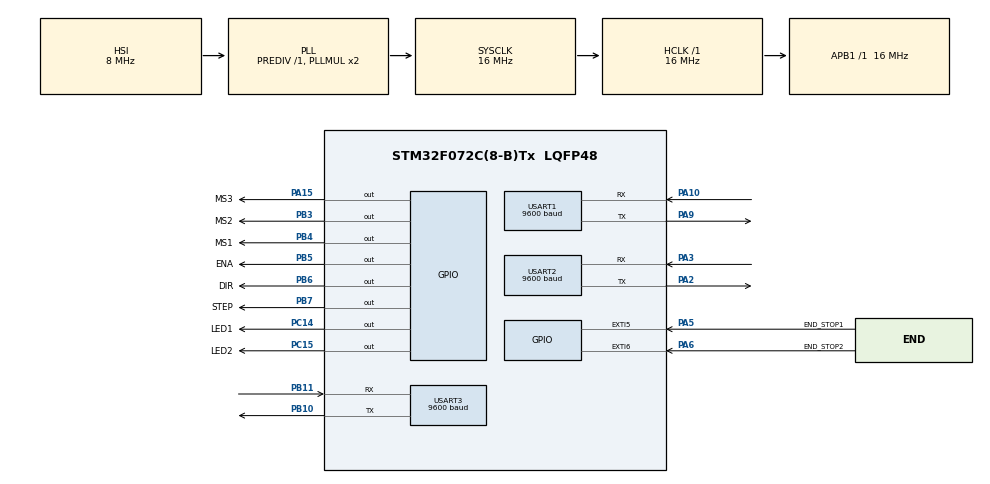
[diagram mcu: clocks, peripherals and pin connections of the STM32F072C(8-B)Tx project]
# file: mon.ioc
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Mcu.Family=STM32F0
Mcu.Name=STM32F072C(8-B)Tx
Mcu.Package=LQFP48
NVIC.EXTI4_15_IRQn=true\:0\:0\:false\:false\:true\:true
NVIC.USART1_IRQn=true\:0\:0\:false\:false\:true\:true
NVIC.USART2_IRQn=true\:0\:0\:false\:false\:true\:true
NVIC.USART3_4_IRQn=true\:0\:0\:false\:false\:true\:true
PA10.Mode=Asynchronous
PA10.Signal=USART1_RX
PA13.Mode=Serial_Wire
PA13.Signal=SYS_SWDIO
PA14.Mode=Serial_Wire
PA14.Signal=SYS_SWCLK
PA15.GPIO_Label=MS3
PA15.Signal=GPIO_Output
PA2.Mode=Asynchronous
PA2.Signal=USART2_TX
PA3.Mode=Asynchronous
PA3.Signal=USART2_RX
PA5.GPIO_Label=END_STOP1
PA5.Signal=GPXTI5
PA6.GPIO_Label=END_STOP2
PA6.Signal=GPXTI6
PA9.Mode=Asynchronous
PA9.Signal=USART1_TX
PB10.Mode=Asynchronous
PB10.Signal=USART3_TX
PB11.Mode=Asynchronous
PB11.Signal=USART3_RX
PB3.GPIO_Label=MS2
PB3.Signal=GPIO_Output
PB4.GPIO_Label=MS1
PB4.Signal=GPIO_Output
PB5.GPIO_Label=ENA
PB5.Signal=GPIO_Output
PB6.GPIO_Label=DIR
PB6.Signal=GPIO_Output
PB7.GPIO_Label=STEP
PB7.Signal=GPIO_Output
PC14-OSC32_IN.GPIO_Label=LED1
PC14-OSC32_IN.Signal=GPIO_Output
PC15-OSC32_OUT.GPIO_Label=LED2
PC15-OSC32_OUT.Signal=GPIO_Output
ProjectManager.HeapSize=0x200
ProjectManager.StackSize=0x400
ProjectManager.TargetToolchain=Makefile
RCC.AHBFreq_Value=16000000
RCC.APB1Freq_Value=16000000
RCC.APB1TimFreq_Value=16000000
RCC.HCLKFreq_Value=16000000
RCC.SYSCLKFreq_VALUE=16000000
RCC.SYSCLKSource=RCC_SYSCLKSOURCE_PLLCLK
USART1.BaudRate=9600
USART1.VirtualMode-Asynchronous=VM_ASYNC
USART1.WordLength=WORDLENGTH_8B
USART2.BaudRate=9600
USART2.VirtualMode-Asynchronous=VM_ASYNC
USART2.WordLength=WORDLENGTH_8B
USART3.BaudRate=9600
USART3.VirtualMode-Asynchronous=VM_ASYNC
USART3.WordLength=WORDLENGTH_8B
board=mon

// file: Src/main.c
/**
 ******************************************************************************
 * @file           : main.c
 * @brief          : Main program body
 ******************************************************************************
 ** This notice applies to any and all portions of this file
 * that are not between comment pairs USER CODE BEGIN and
 * USER CODE END. Other portions of this file, whether
 * inserted by the user or by software development tools
 * are owned by their respective copyright owners.
 *
 * COPYRIGHT(c) 2018 STMicroelectronics
 *
 * Redistribution and use in source and binary forms, with or without modification,
 * are permitted provided that the following conditions are met:
 *   1. Redistributions of source code must retain the above copyright notice,
 *      this list of conditions and the following disclaimer.
 *   2. Redistributions in binary form must reproduce the above copyright notice,
 *      this list of conditions and the following disclaimer in the documentation
 *      and/or other materials provided with the distribution.
 *   3. Neither the name of STMicroelectronics nor the names of its contributors
 *      may be used to endorse or promote products derived from this software
 *      without specific prior written permission.
 *
 * THIS SOFTWARE IS PROVIDED BY THE COPYRIGHT HOLDERS AND CONTRIBUTORS "AS IS"
 * AND ANY EXPRESS OR IMPLIED WARRANTIES, INCLUDING, BUT NOT LIMITED TO, THE
 * IMPLIED WARRANTIES OF MERCHANTABILITY AND FITNESS FOR A PARTICULAR PURPOSE ARE
 * DISCLAIMED. IN NO EVENT SHALL THE COPYRIGHT HOLDER OR CONTRIBUTORS BE LIABLE
 * FOR ANY DIRECT, INDIRECT, INCIDENTAL, SPECIAL, EXEMPLARY, OR CONSEQUENTIAL
 * DAMAGES (INCLUDING, BUT NOT LIMITED TO, PROCUREMENT OF SUBSTITUTE GOODS OR
 * SERVICES; LOSS OF USE, DATA, OR PROFITS; OR BUSINESS INTERRUPTION) HOWEVER
 * CAUSED AND ON ANY THEORY OF LIABILITY, WHETHER IN CONTRACT, STRICT LIABILITY,
 * OR TORT (INCLUDING NEGLIGENCE OR OTHERWISE) ARISING IN ANY WAY OUT OF THE USE
 * OF THIS SOFTWARE, EVEN IF ADVISED OF THE POSSIBILITY OF SUCH DAMAGE.
 *
 ******************************************************************************
 */
#include "main.h"
#include "stm32f0xx_hal.h"

UART_HandleTypeDef huart1;
UART_HandleTypeDef huart2;
UART_HandleTypeDef huart3;

/* USER CODE BEGIN PV */
/* Private variables ---------------------------------------------------------*/

/* USER CODE END PV */

void SystemClock_Config(void);
static void MX_GPIO_Init(void);
static void MX_USART1_UART_Init(void);
static void MX_USART2_UART_Init(void);
static void MX_USART3_UART_Init(void);

/* USER CODE BEGIN PFP */
/* Private function prototypes -----------------------------------------------*/

/* USER CODE END PFP */

int main(void)
{

    /* MCU Configuration----------------------------------------------------------*/

    /* Reset of all peripherals, Initializes the Flash interface and the Systick. */
    HAL_Init();

    /* Configure the system clock */
    SystemClock_Config();

    /* Initialize all configured peripherals */
    MX_GPIO_Init();
    MX_USART1_UART_Init();
    MX_USART2_UART_Init();
    MX_USART3_UART_Init();

    /* Infinite loop */
    while (1)
    {

    }
} /* main */

void SystemClock_Config(void)
{
    RCC_OscInitTypeDef RCC_OscInitStruct;
    RCC_ClkInitTypeDef RCC_ClkInitStruct;
    RCC_PeriphCLKInitTypeDef PeriphClkInit;

    /**Initializes the CPU, AHB and APB busses clocks
     */
    RCC_OscInitStruct.OscillatorType      = RCC_OSCILLATORTYPE_HSI;
    RCC_OscInitStruct.HSIState            = RCC_HSI_ON;
    RCC_OscInitStruct.HSICalibrationValue = 16;
    RCC_OscInitStruct.PLL.PLLState        = RCC_PLL_ON;
    RCC_OscInitStruct.PLL.PLLSource       = RCC_PLLSOURCE_HSI;
    RCC_OscInitStruct.PLL.PLLMUL          = RCC_PLL_MUL2;
    RCC_OscInitStruct.PLL.PREDIV          = RCC_PREDIV_DIV1;
    if (HAL_RCC_OscConfig(&RCC_OscInitStruct) != HAL_OK)
    {
        _Error_Handler(__FILE__, __LINE__);
    }

    /**Initializes the CPU, AHB and APB busses clocks
     */
    RCC_ClkInitStruct.ClockType = RCC_CLOCKTYPE_HCLK | RCC_CLOCKTYPE_SYSCLK
      | RCC_CLOCKTYPE_PCLK1;
    RCC_ClkInitStruct.SYSCLKSource   = RCC_SYSCLKSOURCE_PLLCLK;
    RCC_ClkInitStruct.AHBCLKDivider  = RCC_SYSCLK_DIV1;
    RCC_ClkInitStruct.APB1CLKDivider = RCC_HCLK_DIV1;

    if (HAL_RCC_ClockConfig(&RCC_ClkInitStruct, FLASH_LATENCY_0) != HAL_OK)
    {
        _Error_Handler(__FILE__, __LINE__);
    }

    PeriphClkInit.PeriphClockSelection = RCC_PERIPHCLK_USART1 | RCC_PERIPHCLK_USART2;
    PeriphClkInit.Usart1ClockSelection = RCC_USART1CLKSOURCE_PCLK1;
    PeriphClkInit.Usart2ClockSelection = RCC_USART2CLKSOURCE_PCLK1;
    if (HAL_RCCEx_PeriphCLKConfig(&PeriphClkInit) != HAL_OK)
    {
        _Error_Handler(__FILE__, __LINE__);
    }

    /**Configure the Systick interrupt time
     */
    HAL_SYSTICK_Config(HAL_RCC_GetHCLKFreq() / 1000);

    /**Configure the Systick
     */
    HAL_SYSTICK_CLKSourceConfig(SYSTICK_CLKSOURCE_HCLK);

    /* SysTick_IRQn interrupt configuration */
    HAL_NVIC_SetPriority(SysTick_IRQn, 0, 0);
} /* SystemClock_Config */

/* USART1 init function */
static void MX_USART1_UART_Init(void)
{
    huart1.Instance                    = USART1;
    huart1.Init.BaudRate               = 9600;
    huart1.Init.WordLength             = UART_WORDLENGTH_8B;
    huart1.Init.StopBits               = UART_STOPBITS_1;
    huart1.Init.Parity                 = UART_PARITY_NONE;
    huart1.Init.Mode                   = UART_MODE_TX_RX;
    huart1.Init.HwFlowCtl              = UART_HWCONTROL_NONE;
    huart1.Init.OverSampling           = UART_OVERSAMPLING_16;
    huart1.Init.OneBitSampling         = UART_ONE_BIT_SAMPLE_DISABLE;
    huart1.AdvancedInit.AdvFeatureInit = UART_ADVFEATURE_NO_INIT;
    if (HAL_UART_Init(&huart1) != HAL_OK)
    {
        _Error_Handler(__FILE__, __LINE__);
    }
}

/* USART2 init function */
static void MX_USART2_UART_Init(void)
{
    huart2.Instance                    = USART2;
    huart2.Init.BaudRate               = 9600;
    huart2.Init.WordLength             = UART_WORDLENGTH_8B;
    huart2.Init.StopBits               = UART_STOPBITS_1;
    huart2.Init.Parity                 = UART_PARITY_NONE;
    huart2.Init.Mode                   = UART_MODE_TX_RX;
    huart2.Init.HwFlowCtl              = UART_HWCONTROL_NONE;
    huart2.Init.OverSampling           = UART_OVERSAMPLING_16;
    huart2.Init.OneBitSampling         = UART_ONE_BIT_SAMPLE_DISABLE;
    huart2.AdvancedInit.AdvFeatureInit = UART_ADVFEATURE_NO_INIT;
    if (HAL_UART_Init(&huart2) != HAL_OK)
    {
        _Error_Handler(__FILE__, __LINE__);
    }
}

/* USART3 init function */
static void MX_USART3_UART_Init(void)
{
    huart3.Instance                    = USART3;
    huart3.Init.BaudRate               = 9600;
    huart3.Init.WordLength             = UART_WORDLENGTH_8B;
    huart3.Init.StopBits               = UART_STOPBITS_1;
    huart3.Init.Parity                 = UART_PARITY_NONE;
    huart3.Init.Mode                   = UART_MODE_TX_RX;
    huart3.Init.HwFlowCtl              = UART_HWCONTROL_NONE;
    huart3.Init.OverSampling           = UART_OVERSAMPLING_16;
    huart3.Init.OneBitSampling         = UART_ONE_BIT_SAMPLE_DISABLE;
    huart3.AdvancedInit.AdvFeatureInit = UART_ADVFEATURE_NO_INIT;
    if (HAL_UART_Init(&huart3) != HAL_OK)
    {
        _Error_Handler(__FILE__, __LINE__);
    }
}

/** Configure pins as
 * Analog
 * Input
 * Output
 * EVENT_OUT
 * EXTI
 */
static void MX_GPIO_Init(void)
{
    GPIO_InitTypeDef GPIO_InitStruct;

    /* GPIO Ports Clock Enable */
    __HAL_RCC_GPIOC_CLK_ENABLE();
    __HAL_RCC_GPIOA_CLK_ENABLE();
    __HAL_RCC_GPIOB_CLK_ENABLE();

    /*Configure GPIO pin Output Level */
    HAL_GPIO_WritePin(GPIOC, LED1_Pin | LED2_Pin, GPIO_PIN_RESET);

    /*Configure GPIO pin Output Level */
    HAL_GPIO_WritePin(MS3_GPIO_Port, MS3_Pin, GPIO_PIN_RESET);

    /*Configure GPIO pin Output Level */
    HAL_GPIO_WritePin(GPIOB, MS2_Pin | MS1_Pin | ENA_Pin | DIR_Pin
      | STEP_Pin, GPIO_PIN_RESET);

    /*Configure GPIO pins : LED1_Pin LED2_Pin */
    GPIO_InitStruct.Pin   = LED1_Pin | LED2_Pin;
    GPIO_InitStruct.Mode  = GPIO_MODE_OUTPUT_PP;
    GPIO_InitStruct.Pull  = GPIO_NOPULL;
    GPIO_InitStruct.Speed = GPIO_SPEED_FREQ_LOW;
    HAL_GPIO_Init(GPIOC, &GPIO_InitStruct);

    /*Configure GPIO pins : END_STOP1_Pin END_STOP2_Pin */
    GPIO_InitStruct.Pin  = END_STOP1_Pin | END_STOP2_Pin;
    GPIO_InitStruct.Mode = GPIO_MODE_IT_RISING;
    GPIO_InitStruct.Pull = GPIO_NOPULL;
    HAL_GPIO_Init(GPIOA, &GPIO_InitStruct);

    /*Configure GPIO pin : MS3_Pin */
    GPIO_InitStruct.Pin   = MS3_Pin;
    GPIO_InitStruct.Mode  = GPIO_MODE_OUTPUT_PP;
    GPIO_InitStruct.Pull  = GPIO_NOPULL;
    GPIO_InitStruct.Speed = GPIO_SPEED_FREQ_LOW;
    HAL_GPIO_Init(MS3_GPIO_Port, &GPIO_InitStruct);

    /*Configure GPIO pins : MS2_Pin MS1_Pin ENA_Pin DIR_Pin
     *                       STEP_Pin */
    GPIO_InitStruct.Pin = MS2_Pin | MS1_Pin | ENA_Pin | DIR_Pin
      | STEP_Pin;
    GPIO_InitStruct.Mode  = GPIO_MODE_OUTPUT_PP;
    GPIO_InitStruct.Pull  = GPIO_NOPULL;
    GPIO_InitStruct.Speed = GPIO_SPEED_FREQ_LOW;
    HAL_GPIO_Init(GPIOB, &GPIO_InitStruct);

    /* EXTI interrupt init*/
    HAL_NVIC_SetPriority(EXTI4_15_IRQn, 0, 0);
    HAL_NVIC_EnableIRQ(EXTI4_15_IRQn);
} /* MX_GPIO_Init */

void _Error_Handler(char *file, int line)
{
    /* USER CODE BEGIN Error_Handler_Debug */
    /* User can add his own implementation to report the HAL error return state */
    while (1)
    { }
    /* USER CODE END Error_Handler_Debug */
}

#ifdef  USE_FULL_ASSERT

/**
 * @brief  Reports the name of the source file and the source line number
 *         where the assert_param error has occurred.
 * @param  file: pointer to the source file name
 * @param  line: assert_param error line source number
 * @retval None
 */
void assert_failed(uint8_t *file, uint32_t line)
{
    /* USER CODE BEGIN 6 */

    /* User can add his own implementation to report the file name and line number,
     * tex: printf("Wrong parameters value: file %s on line %d\r\n", file, line) */
    /* USER CODE END 6 */
}

#endif /* USE_FULL_ASSERT */

/************************ (C) COPYRIGHT STMicroelectronics *****END OF FILE****/
